# MKM34Z7 register map
Vendor: Freescale Semiconductor, Inc.; Series: Kinetis_M; File version: 1.6
CPU: CM0PLUS r0p0, little endian, no MPU, no FPU, VTOR, 2 interrupt priority bits
Registers are 8-bit, read-write, reset 0x0 unless marked. A register's access mark holds for its fields unless they carry their own. Offsets are from the block's base; [hi:lo] are bit positions; {n}, {i} and the like mark numbered series.

## PMC — Power Management Controller
Base 0x4007D000; register names take the prefix PMC_
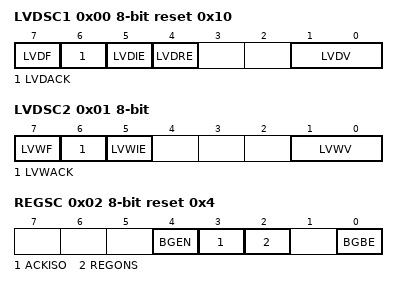
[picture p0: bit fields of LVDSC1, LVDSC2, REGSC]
0x00 LVDSC1 reset 0x10 — Low Voltage Detect Status And Control 1 register
  [7] LVDF ro — Low-Voltage Detect Flag
    0=Low-voltage event not detected; 1=Low-voltage event detected
  [6] LVDACK wo — Low-Voltage Detect Acknowledge
  [5] LVDIE — Low-Voltage Detect Interrupt Enable
    0=Hardware interrupt disabled (use polling); 1=Request a hardware interrupt when LVDF = 1
  [4] LVDRE — Low-Voltage Detect Reset Enable
    0=LVDF does not generate hardware resets; 1=Force an MCU reset when LVDF = 1
  [1:0] LVDV — Low-Voltage Detect Voltage Select
    0=Low trip point selected (V LVD = V LVDL ); 1=High trip point selected (V LVD = V LVDH )
0x01 LVDSC2 — Low Voltage Detect Status And Control 2 register
  [7] LVWF ro — Low-Voltage Warning Flag
    0=Low-voltage warning event not detected; 1=Low-voltage warning event detected
  [6] LVWACK wo — Low-Voltage Warning Acknowledge
  [5] LVWIE — Low-Voltage Warning Interrupt Enable
    0=Hardware interrupt disabled (use polling); 1=Request a hardware interrupt when LVWF = 1
  [1:0] LVWV — Low-Voltage Warning Voltage Select
    0=Low trip point selected (VLVW = VLVW1); 1=Mid 1 trip point selected (VLVW = VLVW2); 2=Mid 2 trip point selected (VLVW = VLVW3); 3=High trip point selected (VLVW = VLVW4)
0x02 REGSC reset 0x4 — Regulator Status And Control register
  [4] BGEN — Bandgap Enable In VLPx Operation
    0=Bandgap voltage reference is disabled in VLPx , and VLLSx modes; 1=Bandgap voltage reference is enabled in VLPx , and VLLSx modes
  [3] ACKISO — Acknowledge Isolation
    0=Peripherals and I/O pads are in normal run state; 1=Certain peripherals and I/O pads are in an isolated and latched state
  [2] REGONS ro — Regulator In Run Regulation Status
    0=Regulator is in stop regulation or in transition to/from it; 1=Regulator is in run regulation
  [0] BGBE — Bandgap Buffer Enable
    0=Bandgap buffer not enabled; 1=Bandgap buffer enabled

## SMC — System Mode Controller
Base 0x4007E000; register names take the prefix SMC_
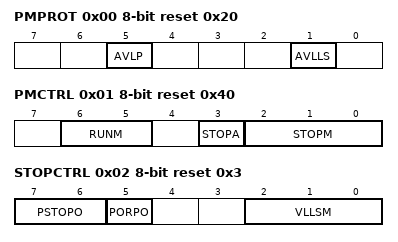
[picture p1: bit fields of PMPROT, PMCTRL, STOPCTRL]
0x00 PMPROT reset 0x20 — Power Mode Protection register
  [5] AVLP — Allow Very-Low-Power Modes
    0=VLPR, VLPW, and VLPS are not allowed; 1=VLPR, VLPW, and VLPS are allowed
  [1] AVLLS — Allow Very-Low-Leakage Stop Mode
    0=Any VLLSx mode is not allowed; 1=Any VLLSx mode is allowed
0x01 PMCTRL reset 0x40 — Power Mode Control register
  [6:5] RUNM — Run Mode Control
    0=Normal Run mode (RUN); 2=Very-Low-Power Run mode (VLPR)
  [3] STOPA ro — Stop Aborted
    0=The previous stop mode entry was successsful; 1=The previous stop mode entry was aborted
  [2:0] STOPM — Stop Mode Control
    0=Normal Stop (STOP); 2=Very-Low-Power Stop (VLPS); 4=Very-Low-Leakage Stop (VLLSx); 6=Reseved
0x02 STOPCTRL reset 0x3 — Stop Control Register
  [7:6] PSTOPO — Partial Stop Option
    0=STOP - Normal Stop mode; 1=PSTOP1 - Partial Stop with both system and bus clocks disabled; 2=PSTOP2 - Partial Stop with system clock disabled and bus clock enabled
  [5] PORPO — POR Power Option
    0=POR detect circuit is enabled in VLLS0; 1=POR detect circuit is disabled in VLLS0
  [2:0] VLLSM — VLLS Mode Control
    {v}=VLLS{v} (v=0..3)
0x03 PMSTAT ro reset 0x4 — Power Mode Status register
  [7:0] PMSTAT — Power Mode Status

## MTB — Micro Trace Buffer
Base 0xF0000000; register names take the prefix MTB_
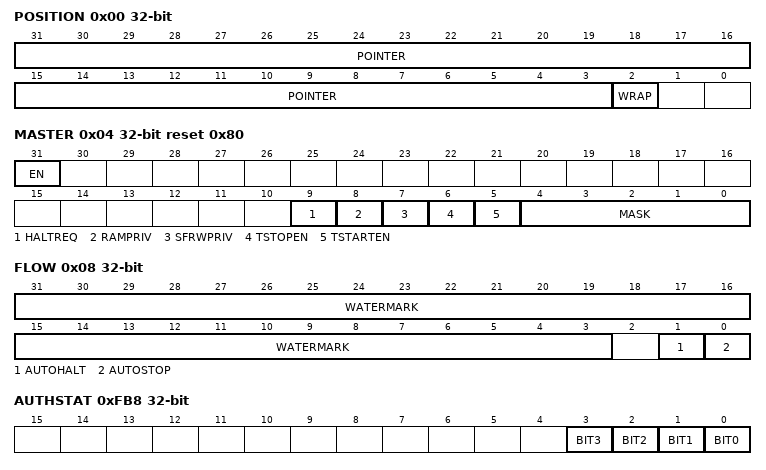
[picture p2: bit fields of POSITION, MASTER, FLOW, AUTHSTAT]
0x00 POSITION 32-bit (reset mask 0x3) — MTB Position Register
  [31:3] POINTER — Trace Packet Address Pointer[28:0]
  [2] WRAP
0x04 MASTER 32-bit reset 0x80 (reset mask 0xFFFFFFE0) — MTB Master Register
  [31] EN — Main Trace Enable
  [9] HALTREQ — Halt Request
  [8] RAMPRIV — RAM Privilege
  [7] SFRWPRIV — Special Function Register Write Privilege
  [6] TSTOPEN — Trace Stop Input Enable
  [5] TSTARTEN — Trace Start Input Enable
  [4:0] MASK
0x08 FLOW 32-bit (reset mask 0x4) — MTB Flow Register
  [31:3] WATERMARK — WATERMARK[28:0]
  [1] AUTOHALT
  [0] AUTOSTOP
0x0C BASE 32-bit ro reset not defined — MTB Base Register
  [31:0] BASEADDR
0xF00 MODECTRL 32-bit ro — Integration Mode Control Register
0xFA0 TAGSET 32-bit ro — Claim TAG Set Register
0xFA4 TAGCLEAR 32-bit ro — Claim TAG Clear Register
0xFB0 LOCKACCESS 32-bit ro
  [31:0] LOCKACCESS — Hardwired to 0x0000_0000
0xFB4 LOCKSTAT 32-bit ro — Lock Status Register
0xFB8 AUTHSTAT 32-bit ro — Authentication Status Register
  [3] BIT3
  [2] BIT2
  [1] BIT1
  [0] BIT0 — Connected to DBGEN.
0xFBC DEVICEARCH 32-bit ro reset 0x47700A31 — Device Architecture Register
0xFC8 DEVICECFG 32-bit ro — Device Configuration Register
0xFCC DEVICETYPID 32-bit ro reset 0x31 — Device Type Identifier Register
0xFD0 PERIPHID{x} (x=4,5,6,7,0,1,2,3; step 0x4) 32-bit ro reset not defined — Peripheral ID Register
  [31:0] PERIPHID
{0xFF0+4i} COMPID{i} (i=0..3) 32-bit ro reset not defined — Component ID Register
  [31:0] COMPID — Component ID
